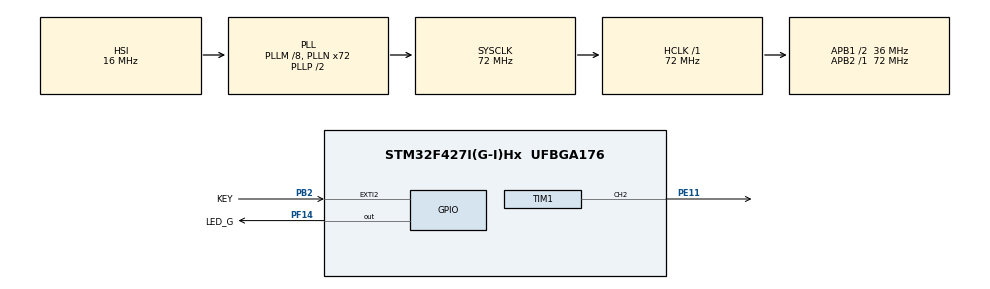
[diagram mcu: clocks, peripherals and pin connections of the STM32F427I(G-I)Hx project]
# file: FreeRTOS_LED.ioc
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FREERTOS.Tasks01=Task_LED_R,0,128,StartTask_LED_R,Default,NULL,Dynamic,NULL,NULL;Task_LED_G,-3,128,StartTask_LED_G,Default,NULL,Dynamic,NULL,NULL
FREERTOS.configIDLE_SHOULD_YIELD=0
FREERTOS.configUSE_NEWLIB_REENTRANT=1
Mcu.Family=STM32F4
Mcu.Name=STM32F427I(G-I)Hx
Mcu.Package=UFBGA176
NVIC.EXTI2_IRQn=true\:6\:0\:true\:false\:true\:true\:true\:true\:true
NVIC.PriorityGroup=NVIC_PRIORITYGROUP_4
NVIC.TIM7_IRQn=true\:15\:0\:false\:false\:true\:false\:false\:true\:true
NVIC.TimeBase=TIM7_IRQn
NVIC.TimeBaseIP=TIM7
PB2/BOOT1.GPIO_Label=KEY
PB2/BOOT1.GPIO_PuPd=GPIO_NOPULL
PB2/BOOT1.Signal=GPXTI2
PC14/OSC32_IN.Mode=LSE-External-Oscillator
PC14/OSC32_IN.Signal=RCC_OSC32_IN
PC15/OSC32_OUT.Mode=LSE-External-Oscillator
PC15/OSC32_OUT.Signal=RCC_OSC32_OUT
PE11.Signal=S_TIM1_CH2
PF14.GPIO_Label=LED_G
PF14.PinState=GPIO_PIN_SET
PF14.Signal=GPIO_Output
PH0/OSC_IN.Mode=HSE-External-Oscillator
PH0/OSC_IN.Signal=RCC_OSC_IN
PH1/OSC_OUT.Mode=HSE-External-Oscillator
PH1/OSC_OUT.Signal=RCC_OSC_OUT
ProjectManager.HeapSize=0x600
ProjectManager.StackSize=0x400
ProjectManager.TargetToolchain=STM32CubeIDE
RCC.48MHZClocksFreq_Value=36000000
RCC.AHBFreq_Value=72000000
RCC.APB1CLKDivider=RCC_HCLK_DIV2
RCC.APB1Freq_Value=36000000
RCC.APB1TimFreq_Value=72000000
RCC.APB2Freq_Value=72000000
RCC.APB2TimFreq_Value=72000000
RCC.CortexFreq_Value=72000000
RCC.HCLKFreq_Value=72000000
RCC.HSE_VALUE=25000000
RCC.HSI_VALUE=16000000
RCC.PLLM=8
RCC.PLLN=72
RCC.SYSCLKFreq_VALUE=72000000
RCC.SYSCLKSource=RCC_SYSCLKSOURCE_PLLCLK
RCC.VCOOutputFreq_Value=144000000
SH.S_TIM1_CH2.0=TIM1_CH2,PWM Generation2 CH2
TIM1.Channel-PWM\ Generation2\ CH2=TIM_CHANNEL_2
TIM1.Period=1000 - 1
TIM1.Prescaler=72 - 1
VP_FREERTOS_VS_CMSIS_V1.Mode=CMSIS_V1
VP_SYS_VS_tim7.Mode=TIM7
board=custom

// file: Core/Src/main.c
/* USER CODE BEGIN Header */
/**
  ******************************************************************************
  * @file           : main.c
  * @brief          : Main program body
  ******************************************************************************
  * @attention
  *
  * Copyright (c) 2023 STMicroelectronics.
  * All rights reserved.
  *
  * This software is licensed under terms that can be found in the LICENSE file
  * in the root directory of this software component.
  * If no LICENSE file comes with this software, it is provided AS-IS.
  *
  ******************************************************************************
  */
/* USER CODE END Header */
#include "main.h"
#include "cmsis_os.h"
#include "tim.h"
#include "gpio.h"

void SystemClock_Config(void);
void MX_FREERTOS_Init(void);

/* USER CODE BEGIN 0 */
void HAL_GPIO_EXTI_Callback(uint16_t GPIO_Pin)//中断回调函数
{
	if (GPIO_Pin == KEY_Pin)
	{
		LED_G_Toggle();
	}
}
/* USER CODE END 0 */

int main(void)
{

  /* MCU Configuration--------------------------------------------------------*/

  /* Reset of all peripherals, Initializes the Flash interface and the Systick. */
  HAL_Init();

  /* Configure the system clock */
  SystemClock_Config();

  /* Initialize all configured peripherals */
  MX_GPIO_Init();
  MX_TIM1_Init();
  /* USER CODE BEGIN 2 */
	HAL_TIM_PWM_Start(&htim1, TIM_CHANNEL_2);
    //以下默认注释，若需要查看任务1，2，3的运行情况，可取消注释
	//任务1：实现呼吸灯效果；（定时器及 pwm）
	LED_R_Breath();//呼吸灯,函数内有死循环，如要检查以下任务，请注释掉

	//任务2：实现按键控制灯的开关；（中断）,请往上查找中断回调函数

	//任务3：使用 freertos 点亮 RGB 三种颜色的灯；（freertos）
	//任务3在freertos.c中

  /* USER CODE END 2 */

  /* Call init function for freertos objects (in freertos.c) */
  MX_FREERTOS_Init();

  /* Start scheduler */
  osKernelStart();

  /* We should never get here as control is now taken by the scheduler */
  /* Infinite loop */
  while (1)
  {

  }
}

void SystemClock_Config(void)
{
  RCC_OscInitTypeDef RCC_OscInitStruct = {0};
  RCC_ClkInitTypeDef RCC_ClkInitStruct = {0};

  /** Configure the main internal regulator output voltage
  */
  __HAL_RCC_PWR_CLK_ENABLE();
  __HAL_PWR_VOLTAGESCALING_CONFIG(PWR_REGULATOR_VOLTAGE_SCALE3);

  /** Initializes the RCC Oscillators according to the specified parameters
  * in the RCC_OscInitTypeDef structure.
  */
  RCC_OscInitStruct.OscillatorType = RCC_OSCILLATORTYPE_HSI;
  RCC_OscInitStruct.HSIState = RCC_HSI_ON;
  RCC_OscInitStruct.HSICalibrationValue = RCC_HSICALIBRATION_DEFAULT;
  RCC_OscInitStruct.PLL.PLLState = RCC_PLL_ON;
  RCC_OscInitStruct.PLL.PLLSource = RCC_PLLSOURCE_HSI;
  RCC_OscInitStruct.PLL.PLLM = 8;
  RCC_OscInitStruct.PLL.PLLN = 72;
  RCC_OscInitStruct.PLL.PLLP = RCC_PLLP_DIV2;
  RCC_OscInitStruct.PLL.PLLQ = 4;
  if (HAL_RCC_OscConfig(&RCC_OscInitStruct) != HAL_OK)
  {
    Error_Handler();
  }

  /** Initializes the CPU, AHB and APB buses clocks
  */
  RCC_ClkInitStruct.ClockType = RCC_CLOCKTYPE_HCLK|RCC_CLOCKTYPE_SYSCLK
                              |RCC_CLOCKTYPE_PCLK1|RCC_CLOCKTYPE_PCLK2;
  RCC_ClkInitStruct.SYSCLKSource = RCC_SYSCLKSOURCE_PLLCLK;
  RCC_ClkInitStruct.AHBCLKDivider = RCC_SYSCLK_DIV1;
  RCC_ClkInitStruct.APB1CLKDivider = RCC_HCLK_DIV2;
  RCC_ClkInitStruct.APB2CLKDivider = RCC_HCLK_DIV1;

  if (HAL_RCC_ClockConfig(&RCC_ClkInitStruct, FLASH_LATENCY_2) != HAL_OK)
  {
    Error_Handler();
  }
}

void HAL_TIM_PeriodElapsedCallback(TIM_HandleTypeDef *htim)
{
  if (htim->Instance == TIM7) {
    HAL_IncTick();
  }
}

void Error_Handler(void)
{
  __disable_irq();
  while (1)
  {
  }
}

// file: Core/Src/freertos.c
/* USER CODE BEGIN Header */
/**
  ******************************************************************************
  * File Name          : freertos.c
  * Description        : Code for freertos applications
  ******************************************************************************
  * @attention
  *
  * Copyright (c) 2023 STMicroelectronics.
  * All rights reserved.
  *
  * This software is licensed under terms that can be found in the LICENSE file
  * in the root directory of this software component.
  * If no LICENSE file comes with this software, it is provided AS-IS.
  *
  ******************************************************************************
  */
/* USER CODE END Header */

#include "FreeRTOS.h"
#include "task.h"
#include "main.h"
#include "cmsis_os.h"

osThreadId Task_LED_RHandle;
osThreadId Task_LED_GHandle;

void StartTask_LED_R(void const * argument);
void StartTask_LED_G(void const * argument);

void MX_FREERTOS_Init(void); /* (MISRA C 2004 rule 8.1) */

/* GetIdleTaskMemory prototype (linked to static allocation support) */
void vApplicationGetIdleTaskMemory( StaticTask_t **ppxIdleTaskTCBBuffer, StackType_t **ppxIdleTaskStackBuffer, uint32_t *pulIdleTaskStackSize );

/* USER CODE BEGIN GET_IDLE_TASK_MEMORY */
static StaticTask_t xIdleTaskTCBBuffer;
static StackType_t xIdleStack[configMINIMAL_STACK_SIZE];

void vApplicationGetIdleTaskMemory( StaticTask_t **ppxIdleTaskTCBBuffer, StackType_t **ppxIdleTaskStackBuffer, uint32_t *pulIdleTaskStackSize )
{
  *ppxIdleTaskTCBBuffer = &xIdleTaskTCBBuffer;
  *ppxIdleTaskStackBuffer = &xIdleStack[0];
  *pulIdleTaskStackSize = configMINIMAL_STACK_SIZE;
  /* place for user code */
}
/* USER CODE END GET_IDLE_TASK_MEMORY */

void MX_FREERTOS_Init(void) {

  /* Create the thread(s) */
  /* definition and creation of Task_LED_R */
  osThreadDef(Task_LED_R, StartTask_LED_R, osPriorityNormal, 0, 128);
  Task_LED_RHandle = osThreadCreate(osThread(Task_LED_R), NULL);

  /* definition and creation of Task_LED_G */
  osThreadDef(Task_LED_G, StartTask_LED_G, osPriorityIdle, 0, 128);
  Task_LED_GHandle = osThreadCreate(osThread(Task_LED_G), NULL);

}

void StartTask_LED_R(void const * argument)
{
  /* USER CODE BEGIN StartTask_LED_R */
  /* Infinite loop */
  for(;;)
  {
      LED_R_Toggle(500);
    osDelay(1);
  }
  /* USER CODE END StartTask_LED_R */
}

void StartTask_LED_G(void const * argument)
{
  /* USER CODE BEGIN StartTask_LED_G */
  /* Infinite loop */
  for(;;)
  {
      LED_G_Toggle();
      HAL_Delay(1000);
    osDelay(1);
  }
  /* USER CODE END StartTask_LED_G */
}
